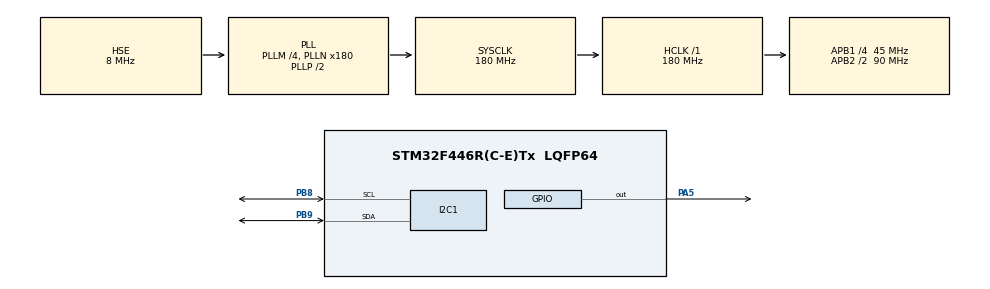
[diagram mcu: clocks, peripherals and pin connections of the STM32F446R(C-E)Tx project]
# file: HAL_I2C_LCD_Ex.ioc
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Mcu.Family=STM32F4
Mcu.Name=STM32F446R(C-E)Tx
Mcu.Package=LQFP64
NVIC.PriorityGroup=NVIC_PRIORITYGROUP_4
PA5.Signal=GPIO_Output
PB8.Mode=I2C
PB8.Signal=I2C1_SCL
PB9.Mode=I2C
PB9.Signal=I2C1_SDA
PH0-OSC_IN.Mode=HSE-External-Oscillator
PH0-OSC_IN.Signal=RCC_OSC_IN
PH1-OSC_OUT.Mode=HSE-External-Oscillator
PH1-OSC_OUT.Signal=RCC_OSC_OUT
ProjectManager.HeapSize=0x200
ProjectManager.StackSize=0x400
ProjectManager.TargetToolchain=MDK-ARM V5
RCC.AHBFreq_Value=180000000
RCC.APB1CLKDivider=RCC_HCLK_DIV4
RCC.APB1Freq_Value=45000000
RCC.APB1TimFreq_Value=90000000
RCC.APB2CLKDivider=RCC_HCLK_DIV2
RCC.APB2Freq_Value=90000000
RCC.APB2TimFreq_Value=180000000
RCC.CortexFreq_Value=180000000
RCC.HCLKFreq_Value=180000000
RCC.HSE_VALUE=8000000
RCC.PLLM=4
RCC.PLLN=180
RCC.PLLSourceVirtual=RCC_PLLSOURCE_HSE
RCC.SYSCLKFreq_VALUE=180000000
RCC.SYSCLKSource=RCC_SYSCLKSOURCE_PLLCLK
RCC.USBFreq_Value=180000000
RCC.VCOOutputFreq_Value=360000000
board=custom

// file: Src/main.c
/* USER CODE BEGIN Header */
/**
  ******************************************************************************
  * @file           : main.c
  * @brief          : Main program body
  ******************************************************************************
  * @attention
  *
  * <h2><center>&copy; Copyright (c) 2020 STMicroelectronics.
  * All rights reserved.</center></h2>
  *
  * This software component is licensed by ST under BSD 3-Clause license,
  * the "License"; You may not use this file except in compliance with the
  * License. You may obtain a copy of the License at:
  *                        opensource.org/licenses/BSD-3-Clause
  *
  ******************************************************************************
  */
/* USER CODE END Header */

#include "main.h"

/* USER CODE BEGIN Includes */
#include "i2c-lcd.h"
/* USER CODE END Includes */

I2C_HandleTypeDef hi2c1;

/* USER CODE BEGIN PV */
char heart[8]={0x0,0xA,0x1F,0x1F,0x1F,0xE,0x4,0x0};
char bell[8]={0x0,0x4,0xE,0xE,0xE,0xE,0x1F,0x4};
/* USER CODE END PV */

void SystemClock_Config(void);
static void MX_GPIO_Init(void);
static void MX_I2C1_Init(void);

/* USER CODE BEGIN 0 */
void lcd_create_ch(char *ch,uint8_t num)
{
	uint8_t i=0;
	lcd_send_cmd(0x40+num*8);		//	sets cgram adress

	while(i<7)
	{
		lcd_send_data(ch[i]);
		i++;
	}

}

/* USER CODE END 0 */

int main(void)
{

  /* MCU Configuration--------------------------------------------------------*/

  /* Reset of all peripherals, Initializes the Flash interface and the Systick. */
  HAL_Init();

  /* Configure the system clock */
  SystemClock_Config();

  /* Initialize all configured peripherals */
  MX_GPIO_Init();
  MX_I2C1_Init();
  /* USER CODE BEGIN 2 */
	lcd_create_ch(heart,0);
	lcd_create_ch(bell,1);
	lcd_init();
	lcd_put_cur(0,2);
	lcd_send_string("OGUZHAN ESIN");
	lcd_put_cur(1,0);
	lcd_send_data(0x0);
	lcd_put_cur(1,15);
	lcd_send_data(0x1);

/*	Scan i2c slave adrress*/
//	for(uint8_t i=0;i<0xFF;i++)
//	{
//		if(HAL_I2C_IsDeviceReady(&hi2c1,i,1,10)==HAL_OK)
//		{
//			HAL_GPIO_TogglePin(GPIOA,GPIO_PIN_5);
//			break;
//		}
//	}

  /* USER CODE END 2 */

  /* Infinite loop */
  while (1)
  {

  }
}

void SystemClock_Config(void)
{
  RCC_OscInitTypeDef RCC_OscInitStruct = {0};
  RCC_ClkInitTypeDef RCC_ClkInitStruct = {0};

  /** Configure the main internal regulator output voltage
  */
  __HAL_RCC_PWR_CLK_ENABLE();
  __HAL_PWR_VOLTAGESCALING_CONFIG(PWR_REGULATOR_VOLTAGE_SCALE1);
  /** Initializes the CPU, AHB and APB busses clocks
  */
  RCC_OscInitStruct.OscillatorType = RCC_OSCILLATORTYPE_HSE;
  RCC_OscInitStruct.HSEState = RCC_HSE_ON;
  RCC_OscInitStruct.PLL.PLLState = RCC_PLL_ON;
  RCC_OscInitStruct.PLL.PLLSource = RCC_PLLSOURCE_HSE;
  RCC_OscInitStruct.PLL.PLLM = 4;
  RCC_OscInitStruct.PLL.PLLN = 180;
  RCC_OscInitStruct.PLL.PLLP = RCC_PLLP_DIV2;
  RCC_OscInitStruct.PLL.PLLQ = 2;
  RCC_OscInitStruct.PLL.PLLR = 2;
  if (HAL_RCC_OscConfig(&RCC_OscInitStruct) != HAL_OK)
  {
    Error_Handler();
  }
  /** Activate the Over-Drive mode
  */
  if (HAL_PWREx_EnableOverDrive() != HAL_OK)
  {
    Error_Handler();
  }
  /** Initializes the CPU, AHB and APB busses clocks
  */
  RCC_ClkInitStruct.ClockType = RCC_CLOCKTYPE_HCLK|RCC_CLOCKTYPE_SYSCLK
                              |RCC_CLOCKTYPE_PCLK1|RCC_CLOCKTYPE_PCLK2;
  RCC_ClkInitStruct.SYSCLKSource = RCC_SYSCLKSOURCE_PLLCLK;
  RCC_ClkInitStruct.AHBCLKDivider = RCC_SYSCLK_DIV1;
  RCC_ClkInitStruct.APB1CLKDivider = RCC_HCLK_DIV4;
  RCC_ClkInitStruct.APB2CLKDivider = RCC_HCLK_DIV2;

  if (HAL_RCC_ClockConfig(&RCC_ClkInitStruct, FLASH_LATENCY_5) != HAL_OK)
  {
    Error_Handler();
  }
}

static void MX_I2C1_Init(void)
{

  hi2c1.Instance = I2C1;
  hi2c1.Init.ClockSpeed = 100000;
  hi2c1.Init.DutyCycle = I2C_DUTYCYCLE_2;
  hi2c1.Init.OwnAddress1 = 0;
  hi2c1.Init.AddressingMode = I2C_ADDRESSINGMODE_7BIT;
  hi2c1.Init.DualAddressMode = I2C_DUALADDRESS_DISABLE;
  hi2c1.Init.OwnAddress2 = 0;
  hi2c1.Init.GeneralCallMode = I2C_GENERALCALL_DISABLE;
  hi2c1.Init.NoStretchMode = I2C_NOSTRETCH_DISABLE;
  if (HAL_I2C_Init(&hi2c1) != HAL_OK)
  {
    Error_Handler();
  }

}

static void MX_GPIO_Init(void)
{
  GPIO_InitTypeDef GPIO_InitStruct = {0};

  /* GPIO Ports Clock Enable */
  __HAL_RCC_GPIOH_CLK_ENABLE();
  __HAL_RCC_GPIOA_CLK_ENABLE();
  __HAL_RCC_GPIOB_CLK_ENABLE();

  /*Configure GPIO pin Output Level */
  HAL_GPIO_WritePin(GPIOA, GPIO_PIN_5, GPIO_PIN_RESET);

  /*Configure GPIO pin : PA5 */
  GPIO_InitStruct.Pin = GPIO_PIN_5;
  GPIO_InitStruct.Mode = GPIO_MODE_OUTPUT_PP;
  GPIO_InitStruct.Pull = GPIO_NOPULL;
  GPIO_InitStruct.Speed = GPIO_SPEED_FREQ_LOW;
  HAL_GPIO_Init(GPIOA, &GPIO_InitStruct);

}

void Error_Handler(void)
{
}

/************************ (C) COPYRIGHT STMicroelectronics *****END OF FILE****/
